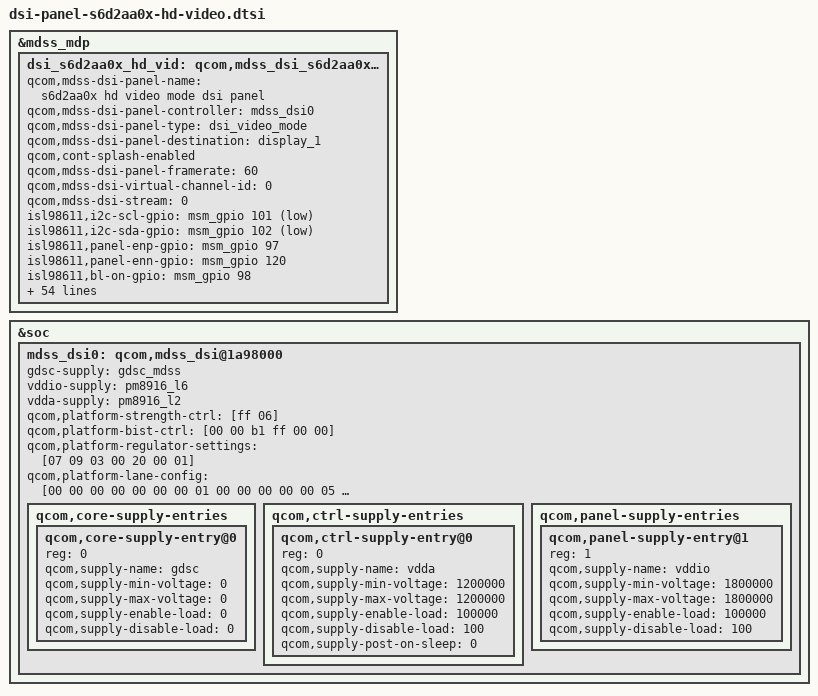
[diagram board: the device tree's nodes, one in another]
/* Copyright (c) 2013, The Linux Foundation. All rights reserved.
 *
 * This program is free software; you can redistribute it and/or modify
 * it under the terms of the GNU General Public License version 2 and
 * only version 2 as published by the Free Software Foundation.
 *
 * This program is distributed in the hope that it will be useful,
 * but WITHOUT ANY WARRANTY; without even the implied warranty of
 * MERCHANTABILITY or FITNESS FOR A PARTICULAR PURPOSE.  See the
 * GNU General Public License for more details.
 */

/*---------------------------------------------------------------------------
 * This file is autogenerated file using gcdb parser. Please do not edit it.
 * Update input XML file to add a new entry or update variable in this file
 * VERSION = "1.0"
 *---------------------------------------------------------------------------*/
&mdss_mdp {
	dsi_s6d2aa0x_hd_vid: qcom,mdss_dsi_s6d2aa0x_hd_video {
		qcom,mdss-dsi-panel-name = "s6d2aa0x hd video mode dsi panel";
		qcom,mdss-dsi-panel-controller = <&mdss_dsi0>;
		qcom,mdss-dsi-panel-type = "dsi_video_mode";
		qcom,mdss-dsi-panel-destination = "display_1";
		qcom,cont-splash-enabled;
		qcom,mdss-dsi-panel-framerate = <60>;
		qcom,mdss-dsi-virtual-channel-id = <0>;
		qcom,mdss-dsi-stream = <0>;
		isl98611,i2c-scl-gpio = <&msm_gpio 101 1>;
		isl98611,i2c-sda-gpio = <&msm_gpio 102 1>;
		isl98611,panel-enp-gpio = <&msm_gpio 97 0>;
		isl98611,panel-enn-gpio = <&msm_gpio 120 0>;
		isl98611,bl-on-gpio = <&msm_gpio 98 0>;
		qcom,lcd-esd-det-gpio = <&msm_gpio 69 0>;
		qcom,mdss-dsi-panel-width = <720>;
		qcom,mdss-dsi-panel-height = <1280>;
		qcom,mdss-dsi-h-front-porch = <134>;
		qcom,mdss-dsi-h-back-porch = <117>;
		qcom,mdss-dsi-h-pulse-width = <4>;
		qcom,mdss-dsi-h-sync-skew = <0>;
		qcom,mdss-dsi-v-back-porch = <6>;
		qcom,mdss-dsi-v-front-porch = <8>;
		qcom,mdss-dsi-v-pulse-width = <2>;
		qcom,mdss-dsi-h-left-border = <0>;
		qcom,mdss-dsi-h-right-border = <0>;
		qcom,mdss-dsi-v-top-border = <0>;
		qcom,mdss-dsi-v-bottom-border = <0>;
		qcom,mdss-dsi-bpp = <24>;
		qcom,mdss-dsi-underflow-color = <0xff>;
		qcom,mdss-dsi-border-color = <0>;
		qcom,mdss-dsi-on-command = [
			39 01 00 00 78 00 02 11 00
			39 01 00 00 00 00 02 B0 00
			39 01 00 00 00 00 1F C9 0C 19 1C 28 32 3E 48 57 3B 43 51 5F 68 70 7F 0C 19 1C 28 32 3E 48 57 3B 43 51 5F 68 70 7F
			39 01 00 00 00 00 14 CA 01 00 00 00 00 C0 00 00 FF 00 FE B6 00 00 00 00 00 FC 00
			39 01 00 00 00 00 06 B7 78 64 10 64 AB
			39 01 00 00 00 00 12 B8 B4 40 43 49 55 62 71 82 94 A8 B9 CB DB E9 F5 FC FF
			39 01 00 00 00 00 03 B9 B4 A0
			39 01 00 00 00 00 02 BB 2E
			39 01 00 00 00 00 07 BC 01 38 04 04 00 00
			39 01 00 00 14 00 02 36 00
			39 01 00 00 00 00 02 53 26
			39 01 00 00 00 00 02 55 00
			39 01 00 00 00 00 02 5E 00
			39 01 00 00 0A 00 02 29 00
			39 01 00 00 00 00 02 B0 00
		];
		qcom,mdss-dsi-off-command = [
			05 01 00 00 32 00 02 28 00
			05 01 00 00 78 00 02 10 00
		];
		qcom,mdss-dsi-on-command-state = "dsi_lp_mode";
		qcom,mdss-dsi-off-command-state = "dsi_hs_mode";
		qcom,mdss-dsi-h-sync-pulse = <0>;
		qcom,mdss-dsi-traffic-mode = "burst_mode";
		qcom,mdss-dsi-bllp-eof-power-mode;
		qcom,mdss-dsi-bllp-power-mode;
		qcom,mdss-dsi-lane-0-state;
		qcom,mdss-dsi-lane-1-state;
		qcom,mdss-dsi-lane-2-state;
		qcom,mdss-dsi-lane-3-state;
		qcom,mdss-dsi-panel-timings = [82 1C 12 00 42 44 18 26 24 03 04 00];
		qcom,mdss-dsi-t-clk-post = <0x04>;
		qcom,mdss-dsi-t-clk-pre = <0x1b>;
		qcom,mdss-dsi-bl-min-level = <1>;
		qcom,mdss-dsi-bl-max-level = <255>;
		qcom,mdss-dsi-dma-trigger = "trigger_sw";
		qcom,mdss-dsi-mdp-trigger = "none";
		qcom,mdss-dsi-bl-pmic-control-type = "bl_ctrl_dcs";
		qcom,mdss-dsi-reset-sequence = <0 20>, <1 100>;
		qcom,mdss-pan-physical-width-dimension = <69>;
		qcom,mdss-pan-physical-height-dimension = <124>;
		qcom,mdss-dsi-lp11-init;
		qcom,mdss-dsi-init-delay-us = <20000>;
		qcom,mdss-force-clk-lane-hs = <1>;
		samsung,panel-brightness-cmds = [
			15 01 00 00 05 00 02 51 00
		];
		samsung,panel-cabc-on-cmds = [
			39 00 00 00 05 00 02 55 01
			39 01 00 00 01 00 02 5E 0B
		];
		samsung,panel-cabc-off-cmds = [
			39 00 00 00 05 00 02 55 00
			39 01 00 00 01 00 02 5E 00
		];
		samsung,panel-cabc-cmds-state = "dsi_hs_mode";
	};
};
&soc {
	mdss_dsi0: qcom,mdss_dsi@1a98000 {
		gdsc-supply = <&gdsc_mdss>;
		vddio-supply = <&pm8916_l6>;
		vdda-supply = <&pm8916_l2>;
		qcom,platform-strength-ctrl = [ff 06];
		qcom,platform-bist-ctrl = [00 00 b1 ff 00 00];
		qcom,platform-regulator-settings = [07 09 03 00 20 00 01];
		qcom,platform-lane-config = [00 00 00 00 00 00 00 01 00
			00 00 00 00 05 00 00 01 00
			00 00 00 00 0a 00 00 01 00
			00 00 00 00 0f 00 00 01 00
			00 c0 00 00 00 00 00 01 bb];
		qcom,core-supply-entries {
			#address-cells = <1>;
			#size-cells = <0>;

			qcom,core-supply-entry@0 {
				reg = <0>;
				qcom,supply-name = "gdsc";
				qcom,supply-min-voltage = <0>;
				qcom,supply-max-voltage = <0>;
				qcom,supply-enable-load = <0>;
				qcom,supply-disable-load = <0>;
			};
		};
		qcom,ctrl-supply-entries {
			#address-cells = <1>;
			#size-cells = <0>;

			qcom,ctrl-supply-entry@0 {
				reg = <0>;
				qcom,supply-name = "vdda";
				qcom,supply-min-voltage = <1200000>;
				qcom,supply-max-voltage = <1200000>;
				qcom,supply-enable-load = <100000>;
				qcom,supply-disable-load = <100>;
				qcom,supply-post-on-sleep = <0>;
			};
		};
		qcom,panel-supply-entries {
			#address-cells = <1>;
			#size-cells = <0>;

			qcom,panel-supply-entry@1 {
				reg = <1>;
				qcom,supply-name = "vddio";
				qcom,supply-min-voltage = <1800000>;
				qcom,supply-max-voltage = <1800000>;
				qcom,supply-enable-load = <100000>;
				qcom,supply-disable-load = <100>;
			};
		};
	};
};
